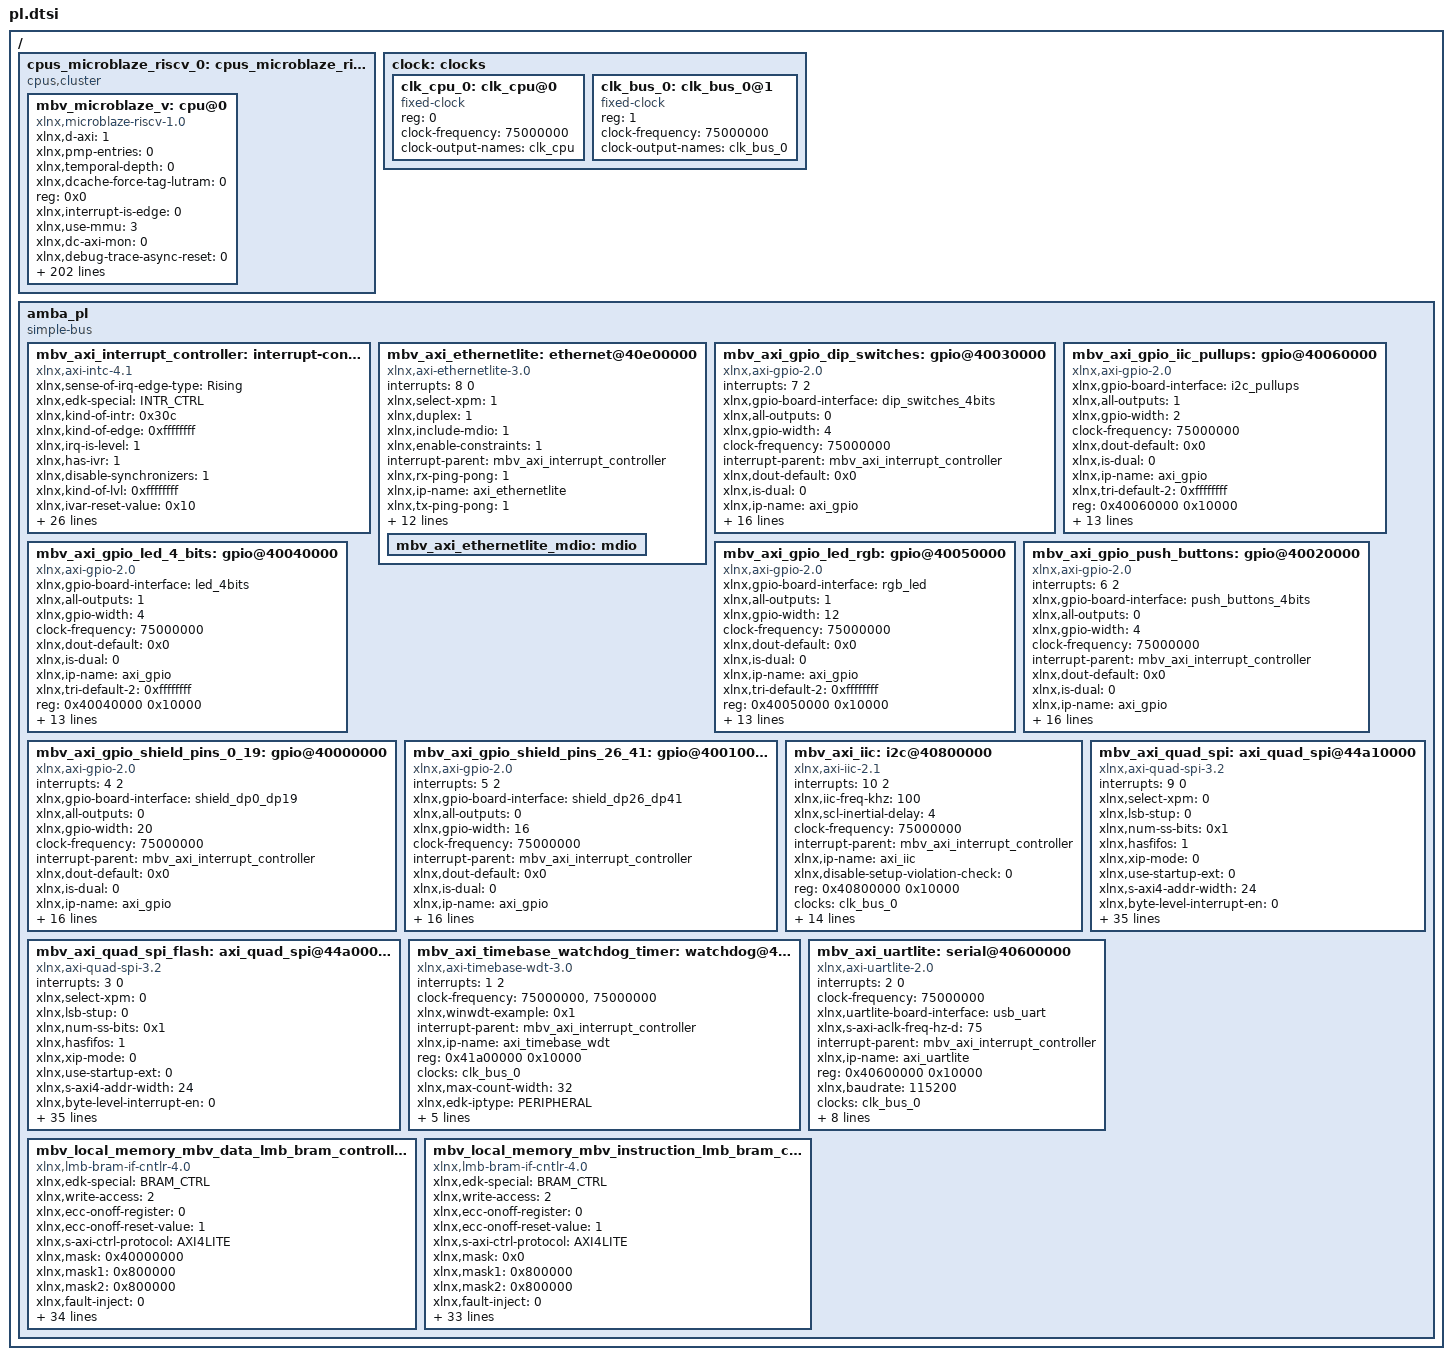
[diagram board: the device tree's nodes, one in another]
/ {
	cpus_microblaze_riscv_0: cpus_microblaze_riscv@0 {
		#cpu-mask-cells = <1>;
		compatible = "cpus,cluster";
		#address-cells = <1>;
		#size-cells = <0>;
		mbv_microblaze_v: cpu@0 {
			xlnx,d-axi = <1>;
			xlnx,pmp-entries = <0>;
			xlnx,temporal-depth = <0>;
			xlnx,dcache-force-tag-lutram = <0>;
			reg = <0x0>;
			xlnx,interrupt-is-edge = <0>;
			xlnx,use-mmu = <3>;
			xlnx,dc-axi-mon = <0>;
			xlnx,debug-trace-async-reset = <0>;
			xlnx,part = "xc7a35ticsg324-1l";
			xlnx,use-config-reset = <0>;
			xlnx,family = "artix7";
			xlnx,use-sleep = <0>;
			xlnx,d-lmb = <1>;
			xlnx,enable-discrete-ports = <0>;
			xlnx,debug-interface = <0>;
			xlnx,use-ext-brk = <0>;
			xlnx,debug-enabled = <1>;
			xlnx,daddr-size = <32>;
			xlnx,use-extended-fsl-instr = <0>;
			xlnx,branch-target-cache-size = <0>;
			bus-handle = <&amba_pl>;
			xlnx,pmp-addr0 = <0x0>;
			xlnx,pmp-addr1 = <0x0>;
			xlnx,pmp-addr2 = <0x0>;
			xlnx,pmp-addr3 = <0x0>;
			xlnx,pmp-addr4 = <0x0>;
			xlnx,edk-special = "microblaze_riscv";
			xlnx,use-dcache = <0>;
			xlnx,pmp-addr5 = <0x0>;
			xlnx,use-muldiv = <2>;
			xlnx,pmp-addr6 = <0x0>;
			xlnx,use-axi-dp-ext-addr = <0>;
			xlnx,pmp-addr7 = <0x0>;
			xlnx,pmp-addr8 = <0x0>;
			xlnx,pmp-addr9 = <0x0>;
			xlnx,i-axi = <0>;
			xlnx,icache-streams = <0>;
			xlnx,i-lmb-has-prot = <0>;
			xlnx,num-sync-ff-dbg-clk = <1>;
			xlnx,icache-byte-size = <8192>;
			xlnx,pmp-addr10 = <0x0>;
			d-cache-size = <8192>;
			xlnx,pmp-addr11 = <0x0>;
			xlnx,pmp-addr12 = <0x0>;
			xlnx,pmp-addr13 = <0x0>;
			xlnx,pmp-addr14 = <0x0>;
			xlnx,pmp-addr15 = <0x0>;
			xlnx,avoid-primitives = <0>;
			xlnx,pmp-addr16 = <0x0>;
			xlnx,pmp-addr17 = <0x0>;
			xlnx,pmp-addr18 = <0x0>;
			xlnx,pdaddr-size = <34>;
			xlnx,pmp-addr19 = <0x0>;
			xlnx,pmp-addr20 = <0x0>;
			xlnx,pmp-addr21 = <0x0>;
			xlnx,i-lmb = <1>;
			xlnx,pmp-addr22 = <0x0>;
			xlnx,lmb-data-size = <32>;
			xlnx,lockstep-select = <0>;
			xlnx,pmp-addr23 = <0x0>;
			timebase-frequency = <75000000>;
			xlnx,pmp-addr24 = <0x0>;
			xlnx,dcache-data-width = <0>;
			xlnx,icache-force-tag-lutram = <0>;
			xlnx,pmp-addr25 = <0x0>;
			xlnx,pmp-addr26 = <0x0>;
			xlnx,use-branch-target-cache = <0>;
			xlnx,pmp-addr27 = <0x0>;
			xlnx,number-of-pc-brk = <8>;
			xlnx,pmp-addr28 = <0x0>;
			xlnx,imprecise-exceptions = <0>;
			xlnx,pmp-addr29 = <0x0>;
			xlnx,pmp-addr30 = <0x0>;
			xlnx,pmp-addr31 = <0x0>;
			xlnx,pmp-addr32 = <0x0>;
			model = "microblaze_riscv,1.0";
			xlnx,pmp-addr33 = <0x0>;
			xlnx,pmp-addr34 = <0x0>;
			xlnx,pmp-addr35 = <0x0>;
			xlnx,pmp-addr36 = <0x0>;
			d-cache-highaddr = <0x3fffffff>;
			xlnx,optimization = <0>;
			xlnx,pmp-addr37 = <0x0>;
			xlnx,pmp-addr38 = <0x0>;
			xlnx,pmp-addr39 = <0x0>;
			xlnx,pmp-addr40 = <0x0>;
			xlnx,pmp-addr41 = <0x0>;
			xlnx,d-lmb-mon = <0>;
			xlnx,pmp-addr42 = <0x0>;
			xlnx,pmp-addr43 = <0x0>;
			xlnx,pmp-addr44 = <0x0>;
			xlnx,pmp-addr45 = <0x0>;
			xlnx,pmp-addr46 = <0x0>;
			xlnx,pmp-addr47 = <0x0>;
			xlnx,pmp-addr48 = <0x0>;
			xlnx,fault-tolerant = <0>;
			xlnx,pmp-addr49 = <0x0>;
			xlnx,pmp-addr50 = <0x0>;
			xlnx,pmp-addr51 = <0x0>;
			xlnx,pmp-enhancements = <0>;
			d-cache-line-size = <16>;
			xlnx,mmu-privileged-instr = <0>;
			xlnx,pmp-addr52 = <0x0>;
			clock-frequency = <75000000>;
			xlnx,pmp-addr53 = <0x0>;
			xlnx,pmp-addr54 = <0x0>;
			xlnx,pmp-addr55 = <0x0>;
			xlnx,i-lmb-protocol = <0>;
			xlnx,pmp-addr56 = <0x0>;
			xlnx,pmp-addr57 = <0x0>;
			xlnx,dp-axi-mon = <0>;
			xlnx,pmp-addr58 = <0x0>;
			xlnx,pmp-addr59 = <0x0>;
			xlnx,pmp-addr60 = <0x0>;
			xlnx,pmp-addr61 = <0x0>;
			xlnx,pmp-addr62 = <0x0>;
			xlnx,pmp-addr63 = <0x0>;
			xlnx,debug-external-trace = <1>;
			xlnx,addr-size = <32>;
			xlnx,debug-num-progbuf = <2>;
			xlnx,debug-event-counters = <13>;
			xlnx,edk-iptype = "PROCESSOR";
			xlnx,debug-latency-counters = <8>;
			xlnx,interconnect = <2>;
			xlnx,edge-is-positive = <1>;
			xlnx,use-icache = <0>;
			xlnx,async-wakeup = <3>;
			xlnx,s-axi = <0>;
			xlnx,use-ext-nm-brk = <0>;
			xlnx,ic-axi-mon = <0>;
			xlnx,archid = <0x1>;
			xlnx,num-sync-ff-clk-irq = <1>;
			xlnx,freq = <75000000>;
			xlnx,lockstep-master = <0>;
			xlnx,pmp-cfg0 = <0x0>;
			xlnx,pmp-cfg1 = <0x0>;
			xlnx,iaddr-size = <32>;
			xlnx,interrupt-mon = <0>;
			xlnx,pmp-cfg2 = <0x0>;
			xlnx,number-of-wr-addr-brk = <4>;
			xlnx,pmp-cfg3 = <0x0>;
			xlnx,pmp-cfg4 = <0x0>;
			xlnx,use-interrupt = <2>;
			xlnx,pmp-cfg5 = <0x0>;
			xlnx,async-interrupt = <1>;
			xlnx,pc-width = <17>;
			xlnx,pmp-cfg6 = <0x0>;
			xlnx,icache-victims = <0>;
			xlnx,pmp-cfg7 = <0x0>;
			xlnx,pmp-cfg8 = <0x0>;
			xlnx,pmp-cfg9 = <0x0>;
			xlnx,use-bitman-a = <1>;
			xlnx,use-bitman-b = <1>;
			xlnx,use-bitman-c = <1>;
			xlnx,i-lmb-mon = <0>;
			xlnx,dcache-byte-size = <8192>;
			xlnx,data-size = <32>;
			compatible = "xlnx,microblaze-riscv-1.0" , "xlnx,microblaze_riscv";
			xlnx,pmp-debug-inhibit = <0x0>;
			xlnx,use-sstc = <1>;
			xlnx,fsl-exception = <0>;
			xlnx,dcache-use-writeback = <0>;
			device_type = "cpu";
			xlnx,impid = <0x1>;
			xlnx,use-bitman-s = <1>;
			xlnx,base-vectors = <0x0>;
			xlnx,icache-line-len = <4>;
			xlnx,d-lmb-has-prot = <0>;
			xlnx,use-barrel = <1>;
			xlnx,misaligned-exceptions = <1>;
			xlnx,piaddr-size = <34>;
			xlnx,use-bitman = <15>;
			xlnx,dcache-line-len = <4>;
			xlnx,num-sync-ff-clk = <2>;
			xlnx,memory-ip-list = "mbv_local_memory_mbv_instruction_lmb_bram_controller_memory" , "mbv_local_memory_mbv_data_lmb_bram_controller_memory";
			xlnx,number-of-rd-addr-brk = <4>;
			xlnx,use-counters = <1>;
			xlnx,lockstep-slave = <0>;
			interrupt-handle = <&mbv_axi_interrupt_controller>;
			xlnx,pmp-cfg10 = <0x0>;
			xlnx,pmp-cfg11 = <0x0>;
			xlnx,debug-profile-size = <0>;
			xlnx,pmp-cfg12 = <0x0>;
			xlnx,pmp-cfg13 = <0x0>;
			xlnx,pmp-cfg14 = <0x0>;
			xlnx,pmp-cfg15 = <0x0>;
			xlnx,debug-counter-width = <64>;
			xlnx,icache-data-width = <0>;
			xlnx,ip-name = "microblaze_riscv";
			xlnx,ip-axi-mon = <0>;
			xlnx,d-lmb-protocol = <0>;
			xlnx,trace = <0>;
			xlnx,ill-instr-exception = <2>;
			xlnx,debug-trace-size = <0>;
			xlnx,pmp-granularity = <2>;
			xlnx,num-sync-ff-dbg-trace-clk = <2>;
			xlnx,ecc-use-ce-exception = <0>;
			xlnx,num-sync-ff-clk-debug = <2>;
			xlnx,use-atomic = <1>;
			xlnx,g-template-list = <0>;
			xlnx,trap-enhancement = <0>;
			xlnx,hartid = <0x0>;
			xlnx,use-fpu = <0>;
			xlnx,use-non-secure = <0>;
			d-cache-baseaddr = <0x0>;
			xlnx,use-compression = <1>;
			xlnx,instr-size = <32>;
			xlnx,fsl-links = <0>;
			xlnx,dcache-victims = <0>;
			xlnx,pmp-read-only = <0x0>;
		};
	};
	clock: clocks {
		#address-cells = <1>;
		#size-cells = <0>;
		clk_cpu_0: clk_cpu@0 {
			compatible = "fixed-clock";
			reg = <0>;
			clock-frequency = <75000000>;
			clock-output-names = "clk_cpu";
			#clock-cells = <0>;
		};
		clk_bus_0: clk_bus_0@1 {
			compatible = "fixed-clock";
			reg = <1>;
			clock-frequency = <75000000>;
			clock-output-names = "clk_bus_0";
			#clock-cells = <0>;
		};
	};
	amba_pl: amba_pl {
		ranges;
		compatible = "simple-bus";
		#address-cells = <1>;
		#size-cells = <1>;
		mbv_axi_interrupt_controller: interrupt-controller@41200000 {
			#interrupt-cells = <2>;
			xlnx,sense-of-irq-edge-type = "Rising";
			xlnx,edk-special = "INTR_CTRL";
			xlnx,kind-of-intr = <0x30c>;
			xlnx,kind-of-edge = <0xffffffff>;
			xlnx,irq-is-level = <1>;
			xlnx,has-ivr = <1>;
			compatible = "xlnx,axi-intc-4.1" , "xlnx,xps-intc-1.00.a";
			xlnx,disable-synchronizers = <1>;
			xlnx,kind-of-lvl = <0xffffffff>;
			xlnx,ivar-reset-value = <0x10>;
			xlnx,irq-active = <0x1>;
			xlnx,en-cascade-mode = <0>;
			xlnx,ip-name = "axi_intc";
			xlnx,has-ilr = <0>;
			reg = <0x41200000 0x10000>;
			xlnx,addr-width = <0x20>;
			xlnx,s-axi-aclk-freq-mhz = <75>;
			xlnx,num-sw-intr = <0>;
			xlnx,irq-connection = <0>;
			xlnx,num-intr-inputs = <0xb>;
			xlnx,has-sie = <1>;
			xlnx,enable-async = <0>;
			xlnx,has-cie = <1>;
			xlnx,num-sync-ff = <2>;
			xlnx,edk-iptype = "PERIPHERAL";
			xlnx,mb-clk-not-connected = <1>;
			xlnx,has-ipr = <1>;
			xlnx,sense-of-irq-level-type = "Active_High";
			xlnx,cascade-master = <0>;
			xlnx,processor-clk-freq-mhz = <75>;
			status = "okay";
			xlnx,is-fast = <0x1>;
			xlnx,has-fast = <1>;
			xlnx,ivar-rst-val = <0x10>;
			interrupt-controller;
			xlnx,async-intr = <0xfffff900>;
			xlnx,name = "mbv_axi_interrupt_controller";
		};
		mbv_axi_ethernetlite: ethernet@40e00000 {
			interrupts = < 8 0 >;
			xlnx,select-xpm = <1>;
			compatible = "xlnx,axi-ethernetlite-3.0" , "xlnx,axi-ethernetlite-3.0" , "xlnx,xps-ethernetlite-1.00.a";
			xlnx,duplex = <1>;
			xlnx,include-mdio = <1>;
			xlnx,enable-constraints = <1>;
			interrupt-parent = <&mbv_axi_interrupt_controller>;
			xlnx,rx-ping-pong = <1>;
			xlnx,ip-name = "axi_ethernetlite";
			xlnx,tx-ping-pong = <1>;
			reg = <0x40e00000 0x10000>;
			xlnx,mii-board-interface = "eth_mii";
			xlnx,mdio-board-interface = "eth_mdio_mdc";
			xlnx,edk-iptype = "PERIPHERAL";
			xlnx,include-global-buffers = <1>;
			local-mac-address = [ 00 0a 23 00 00 00 ];
			status = "okay";
			xlnx,include-internal-loopback = <0>;
			xlnx,use-board-flow;
			xlnx,use-internal = <0>;
			interrupt-names = "ip2intc_irpt";
			xlnx,name = "mbv_axi_ethernetlite";
			xlnx,axi-aclk-freq-mhz = <75>;
			xlnx,s-axi-id-width = <1>;
			mbv_axi_ethernetlite_mdio: mdio {
				#address-cells = <1>;
				#size-cells = <0>;
			};
		};
		mbv_axi_gpio_dip_switches: gpio@40030000 {
			#interrupt-cells = <2>;
			interrupts = < 7 2 >;
			xlnx,gpio-board-interface = "dip_switches_4bits";
			compatible = "xlnx,axi-gpio-2.0" , "xlnx,xps-gpio-1.00.a";
			xlnx,all-outputs = <0>;
			#gpio-cells = <2>;
			xlnx,gpio-width = <4>;
			clock-frequency = <75000000>;
			interrupt-parent = <&mbv_axi_interrupt_controller>;
			xlnx,dout-default = <0x0>;
			xlnx,is-dual = <0>;
			xlnx,ip-name = "axi_gpio";
			xlnx,tri-default-2 = <0xffffffff>;
			reg = <0x40030000 0x10000>;
			xlnx,all-inputs-2 = <0>;
			clocks = <&clk_bus_0>;
			xlnx,all-outputs-2 = <0>;
			gpio-controller;
			xlnx,interrupt-present = <1>;
			xlnx,gpio2-board-interface = "Custom";
			xlnx,edk-iptype = "PERIPHERAL";
			xlnx,dout-default-2 = <0x0>;
			status = "okay";
			xlnx,gpio2-width = <32>;
			clock-names = "s_axi_aclk";
			xlnx,use-board-flow;
			interrupt-controller;
			interrupt-names = "ip2intc_irpt";
			xlnx,tri-default = <0xffffffff>;
			xlnx,name = "mbv_axi_gpio_dip_switches";
			xlnx,all-inputs = <1>;
		};
		mbv_axi_gpio_iic_pullups: gpio@40060000 {
			xlnx,gpio-board-interface = "i2c_pullups";
			compatible = "xlnx,axi-gpio-2.0" , "xlnx,xps-gpio-1.00.a";
			xlnx,all-outputs = <1>;
			#gpio-cells = <2>;
			xlnx,gpio-width = <2>;
			clock-frequency = <75000000>;
			xlnx,dout-default = <0x0>;
			xlnx,is-dual = <0>;
			xlnx,ip-name = "axi_gpio";
			xlnx,tri-default-2 = <0xffffffff>;
			reg = <0x40060000 0x10000>;
			xlnx,all-inputs-2 = <0>;
			clocks = <&clk_bus_0>;
			xlnx,all-outputs-2 = <0>;
			gpio-controller;
			xlnx,interrupt-present = <0>;
			xlnx,gpio2-board-interface = "Custom";
			xlnx,edk-iptype = "PERIPHERAL";
			xlnx,dout-default-2 = <0x0>;
			status = "okay";
			xlnx,gpio2-width = <32>;
			clock-names = "s_axi_aclk";
			xlnx,use-board-flow;
			xlnx,tri-default = <0xffffffff>;
			xlnx,name = "mbv_axi_gpio_iic_pullups";
			xlnx,all-inputs = <0>;
		};
		mbv_axi_gpio_led_4_bits: gpio@40040000 {
			xlnx,gpio-board-interface = "led_4bits";
			compatible = "xlnx,axi-gpio-2.0" , "xlnx,xps-gpio-1.00.a";
			xlnx,all-outputs = <1>;
			#gpio-cells = <2>;
			xlnx,gpio-width = <4>;
			clock-frequency = <75000000>;
			xlnx,dout-default = <0x0>;
			xlnx,is-dual = <0>;
			xlnx,ip-name = "axi_gpio";
			xlnx,tri-default-2 = <0xffffffff>;
			reg = <0x40040000 0x10000>;
			xlnx,all-inputs-2 = <0>;
			clocks = <&clk_bus_0>;
			xlnx,all-outputs-2 = <0>;
			gpio-controller;
			xlnx,interrupt-present = <0>;
			xlnx,gpio2-board-interface = "Custom";
			xlnx,edk-iptype = "PERIPHERAL";
			xlnx,dout-default-2 = <0x0>;
			status = "okay";
			xlnx,gpio2-width = <32>;
			clock-names = "s_axi_aclk";
			xlnx,use-board-flow;
			xlnx,tri-default = <0xffffffff>;
			xlnx,name = "mbv_axi_gpio_led_4_bits";
			xlnx,all-inputs = <0>;
		};
		mbv_axi_gpio_led_rgb: gpio@40050000 {
			xlnx,gpio-board-interface = "rgb_led";
			compatible = "xlnx,axi-gpio-2.0" , "xlnx,xps-gpio-1.00.a";
			xlnx,all-outputs = <1>;
			#gpio-cells = <2>;
			xlnx,gpio-width = <12>;
			clock-frequency = <75000000>;
			xlnx,dout-default = <0x0>;
			xlnx,is-dual = <0>;
			xlnx,ip-name = "axi_gpio";
			xlnx,tri-default-2 = <0xffffffff>;
			reg = <0x40050000 0x10000>;
			xlnx,all-inputs-2 = <0>;
			clocks = <&clk_bus_0>;
			xlnx,all-outputs-2 = <0>;
			gpio-controller;
			xlnx,interrupt-present = <0>;
			xlnx,gpio2-board-interface = "Custom";
			xlnx,edk-iptype = "PERIPHERAL";
			xlnx,dout-default-2 = <0x0>;
			status = "okay";
			xlnx,gpio2-width = <32>;
			clock-names = "s_axi_aclk";
			xlnx,use-board-flow;
			xlnx,tri-default = <0xffffffff>;
			xlnx,name = "mbv_axi_gpio_led_rgb";
			xlnx,all-inputs = <0>;
		};
		mbv_axi_gpio_push_buttons: gpio@40020000 {
			#interrupt-cells = <2>;
			interrupts = < 6 2 >;
			xlnx,gpio-board-interface = "push_buttons_4bits";
			compatible = "xlnx,axi-gpio-2.0" , "xlnx,xps-gpio-1.00.a";
			xlnx,all-outputs = <0>;
			#gpio-cells = <2>;
			xlnx,gpio-width = <4>;
			clock-frequency = <75000000>;
			interrupt-parent = <&mbv_axi_interrupt_controller>;
			xlnx,dout-default = <0x0>;
			xlnx,is-dual = <0>;
			xlnx,ip-name = "axi_gpio";
			xlnx,tri-default-2 = <0xffffffff>;
			reg = <0x40020000 0x10000>;
			xlnx,all-inputs-2 = <0>;
			clocks = <&clk_bus_0>;
			xlnx,all-outputs-2 = <0>;
			gpio-controller;
			xlnx,interrupt-present = <1>;
			xlnx,gpio2-board-interface = "Custom";
			xlnx,edk-iptype = "PERIPHERAL";
			xlnx,dout-default-2 = <0x0>;
			status = "okay";
			xlnx,gpio2-width = <32>;
			clock-names = "s_axi_aclk";
			xlnx,use-board-flow;
			interrupt-controller;
			interrupt-names = "ip2intc_irpt";
			xlnx,tri-default = <0xffffffff>;
			xlnx,name = "mbv_axi_gpio_push_buttons";
			xlnx,all-inputs = <1>;
		};
		mbv_axi_gpio_shield_pins_0_19: gpio@40000000 {
			#interrupt-cells = <2>;
			interrupts = < 4 2 >;
			xlnx,gpio-board-interface = "shield_dp0_dp19";
			compatible = "xlnx,axi-gpio-2.0" , "xlnx,xps-gpio-1.00.a";
			xlnx,all-outputs = <0>;
			#gpio-cells = <2>;
			xlnx,gpio-width = <20>;
			clock-frequency = <75000000>;
			interrupt-parent = <&mbv_axi_interrupt_controller>;
			xlnx,dout-default = <0x0>;
			xlnx,is-dual = <0>;
			xlnx,ip-name = "axi_gpio";
			xlnx,tri-default-2 = <0xffffffff>;
			reg = <0x40000000 0x10000>;
			xlnx,all-inputs-2 = <0>;
			clocks = <&clk_bus_0>;
			xlnx,all-outputs-2 = <0>;
			gpio-controller;
			xlnx,interrupt-present = <1>;
			xlnx,gpio2-board-interface = "Custom";
			xlnx,edk-iptype = "PERIPHERAL";
			xlnx,dout-default-2 = <0x0>;
			status = "okay";
			xlnx,gpio2-width = <32>;
			clock-names = "s_axi_aclk";
			xlnx,use-board-flow;
			interrupt-controller;
			interrupt-names = "ip2intc_irpt";
			xlnx,tri-default = <0xffffffff>;
			xlnx,name = "mbv_axi_gpio_shield_pins_0_19";
			xlnx,all-inputs = <0>;
		};
		mbv_axi_gpio_shield_pins_26_41: gpio@40010000 {
			#interrupt-cells = <2>;
			interrupts = < 5 2 >;
			xlnx,gpio-board-interface = "shield_dp26_dp41";
			compatible = "xlnx,axi-gpio-2.0" , "xlnx,xps-gpio-1.00.a";
			xlnx,all-outputs = <0>;
			#gpio-cells = <2>;
			xlnx,gpio-width = <16>;
			clock-frequency = <75000000>;
			interrupt-parent = <&mbv_axi_interrupt_controller>;
			xlnx,dout-default = <0x0>;
			xlnx,is-dual = <0>;
			xlnx,ip-name = "axi_gpio";
			xlnx,tri-default-2 = <0xffffffff>;
			reg = <0x40010000 0x10000>;
			xlnx,all-inputs-2 = <0>;
			clocks = <&clk_bus_0>;
			xlnx,all-outputs-2 = <0>;
			gpio-controller;
			xlnx,interrupt-present = <1>;
			xlnx,gpio2-board-interface = "Custom";
			xlnx,edk-iptype = "PERIPHERAL";
			xlnx,dout-default-2 = <0x0>;
			status = "okay";
			xlnx,gpio2-width = <32>;
			clock-names = "s_axi_aclk";
			xlnx,use-board-flow;
			interrupt-controller;
			interrupt-names = "ip2intc_irpt";
			xlnx,tri-default = <0xffffffff>;
			xlnx,name = "mbv_axi_gpio_shield_pins_26_41";
			xlnx,all-inputs = <0>;
		};
		mbv_axi_iic: i2c@40800000 {
			interrupts = < 10 2 >;
			xlnx,iic-freq-khz = <100>;
			compatible = "xlnx,axi-iic-2.1" , "xlnx,xps-iic-2.00.a";
			xlnx,scl-inertial-delay = <4>;
			clock-frequency = <75000000>;
			interrupt-parent = <&mbv_axi_interrupt_controller>;
			xlnx,ip-name = "axi_iic";
			xlnx,disable-setup-violation-check = <0>;
			reg = <0x40800000 0x10000>;
			clocks = <&clk_bus_0>;
			xlnx,gpo-width = <1>;
			xlnx,edk-iptype = "PERIPHERAL";
			xlnx,static-timing-reg-width = <0>;
			xlnx,sda-level = <1>;
			status = "okay";
			xlnx,use-board-flow;
			xlnx,ten-bit-adr = <0>;
			xlnx,default-value = <0x0>;
			interrupt-names = "iic2intc_irpt";
			xlnx,iic-board-interface = "i2c";
			xlnx,timing-reg-width = <32>;
			xlnx,iic-freq = <100000>;
			xlnx,smbus-pmbus-host = <0>;
			xlnx,name = "mbv_axi_iic";
			xlnx,axi-aclk-freq-mhz = <75>;
			xlnx,sda-inertial-delay = <4>;
		};
		mbv_axi_quad_spi: axi_quad_spi@44a10000 {
			interrupts = < 9 0 >;
			xlnx,select-xpm = <0>;
			compatible = "xlnx,axi-quad-spi-3.2" , "xlnx,xps-spi-2.00.a";
			xlnx,lsb-stup = <0>;
			xlnx,num-ss-bits = <0x1>;
			xlnx,hasfifos = <1>;
			xlnx,xip-mode = <0>;
			xlnx,use-startup-ext = <0>;
			xlnx,s-axi4-addr-width = <24>;
			xlnx,byte-level-interrupt-en = <0>;
			num-cs = <0x1>;
			xlnx,xip-perf-mode = <1>;
			xlnx,sck-ratio = <16>;
			xlnx,s-axi4-id-width = <1>;
			fifo-size = <256>;
			interrupt-parent = <&mbv_axi_interrupt_controller>;
			xlnx,multiples16 = <1>;
			xlnx,master-mode = <1>;
			xlnx,shared-startup = <0>;
			xlnx,ip-name = "axi_quad_spi";
			xlnx,qspi-board-interface = "spi";
			reg = <0x44a10000 0x10000>;
			xlnx,dual-quad-mode = <0>;
			xlnx,new-seq-en = <1>;
			bits-per-word = <32>;
			xlnx,num-transfer-bits = <32>;
			xlnx,spi-memory = <3>;
			xlnx,s-axi4-data-width = <32>;
			xlnx,edk-iptype = "PERIPHERAL";
			xlnx,slaveonly = <0>;
			xlnx,use-startup-int = <0>;
			xlnx,use-startup = <0>;
			xlnx,type-of-axi4-interface = <1>;
			xlnx,async-clk = <0>;
			xlnx,spi-mode = <0>;
			xlnx,sck-ratio1 = <1>;
			status = "okay";
			xlnx,fifo-depth = <256>;
			xlnx,use-board-flow;
			xlnx,uc-family = <0>;
			xlnx,spi-mem-addr-bits = <24>;
			xlnx,axi-interface = <1>;
			interrupt-names = "ip2intc_irpt";
			xlnx,Axi4-address = <0x44a10000>;
			xlnx,fifo-included = <1>;
			xlnx,sub-family = "artix7";
			xlnx,name = "mbv_axi_quad_spi";
		};
		mbv_axi_quad_spi_flash: axi_quad_spi@44a00000 {
			interrupts = < 3 0 >;
			xlnx,select-xpm = <0>;
			compatible = "xlnx,axi-quad-spi-3.2" , "xlnx,xps-spi-2.00.a";
			xlnx,lsb-stup = <0>;
			xlnx,num-ss-bits = <0x1>;
			xlnx,hasfifos = <1>;
			xlnx,xip-mode = <0>;
			xlnx,use-startup-ext = <0>;
			xlnx,s-axi4-addr-width = <24>;
			xlnx,byte-level-interrupt-en = <0>;
			num-cs = <0x1>;
			xlnx,xip-perf-mode = <1>;
			xlnx,sck-ratio = <2>;
			xlnx,s-axi4-id-width = <1>;
			fifo-size = <256>;
			interrupt-parent = <&mbv_axi_interrupt_controller>;
			xlnx,multiples16 = <1>;
			xlnx,master-mode = <1>;
			xlnx,shared-startup = <0>;
			xlnx,ip-name = "axi_quad_spi";
			xlnx,qspi-board-interface = "qspi_flash";
			reg = <0x44a00000 0x10000>;
			xlnx,dual-quad-mode = <0>;
			xlnx,new-seq-en = <1>;
			bits-per-word = <8>;
			xlnx,num-transfer-bits = <8>;
			xlnx,spi-memory = <3>;
			xlnx,s-axi4-data-width = <32>;
			xlnx,edk-iptype = "PERIPHERAL";
			xlnx,slaveonly = <0>;
			xlnx,use-startup-int = <0>;
			xlnx,use-startup = <0>;
			xlnx,type-of-axi4-interface = <1>;
			xlnx,async-clk = <0>;
			xlnx,spi-mode = <2>;
			xlnx,sck-ratio1 = <1>;
			status = "okay";
			xlnx,fifo-depth = <256>;
			xlnx,use-board-flow;
			xlnx,uc-family = <0>;
			xlnx,spi-mem-addr-bits = <24>;
			xlnx,axi-interface = <1>;
			interrupt-names = "ip2intc_irpt";
			xlnx,Axi4-address = <0x44a00000>;
			xlnx,fifo-included = <1>;
			xlnx,sub-family = "artix7";
			xlnx,name = "mbv_axi_quad_spi_flash";
		};
		mbv_axi_timebase_watchdog_timer: watchdog@41a00000 {
			compatible = "xlnx,axi-timebase-wdt-3.0" , "xlnx,xps-timebase-wdt-1.00.a";
			interrupts = < 1 2 >;
			clock-frequency = <75000000> , <75000000>;
			xlnx,winwdt-example = <0x1>;
			interrupt-parent = <&mbv_axi_interrupt_controller>;
			xlnx,ip-name = "axi_timebase_wdt";
			reg = <0x41a00000 0x10000>;
			clocks = <&clk_bus_0>;
			xlnx,max-count-width = <32>;
			xlnx,edk-iptype = "PERIPHERAL";
			xlnx,sst-count-width = <8>;
			xlnx,wdt-enable-once = <0x1>;
			status = "okay";
			interrupt-names = "wdt_interrupt";
			xlnx,enable-window-wdt = <0x1>;
			xlnx,name = "mbv_axi_timebase_watchdog_timer";
			xlnx,wdt-interval = <0x1e>;
		};
		mbv_axi_uartlite: serial@40600000 {
			interrupts = < 2 0 >;
			compatible = "xlnx,axi-uartlite-2.0" , "xlnx,xps-uartlite-1.00.a";
			clock-frequency = <75000000>;
			xlnx,uartlite-board-interface = "usb_uart";
			xlnx,s-axi-aclk-freq-hz-d = <75>;
			interrupt-parent = <&mbv_axi_interrupt_controller>;
			xlnx,ip-name = "axi_uartlite";
			reg = <0x40600000 0x10000>;
			xlnx,baudrate = <115200>;
			clocks = <&clk_bus_0>;
			current-speed = <115200>;
			xlnx,use-parity = <0>;
			xlnx,edk-iptype = "PERIPHERAL";
			xlnx,odd-parity = <0>;
			status = "okay";
			xlnx,use-board-flow;
			interrupt-names = "interrupt";
			xlnx,name = "mbv_axi_uartlite";
			xlnx,data-bits = <8>;
			xlnx,parity = "No_Parity";
		};
		mbv_local_memory_mbv_data_lmb_bram_controller: lmb_bram_if_cntlr@0 {
			xlnx,edk-special = "BRAM_CTRL";
			xlnx,write-access = <2>;
			compatible = "xlnx,lmb-bram-if-cntlr-4.0" , "xlnx,axi-bram-ctrl";
			xlnx,ecc-onoff-register = <0>;
			xlnx,ecc-onoff-reset-value = <1>;
			xlnx,s-axi-ctrl-protocol = "AXI4LITE";
			xlnx,mask = <0x40000000>;
			xlnx,mask1 = <0x800000>;
			xlnx,mask2 = <0x800000>;
			xlnx,fault-inject = <0>;
			xlnx,mask3 = <0x800000>;
			xlnx,ip-name = "lmb_bram_if_cntlr";
			xlnx,arbitration = <0>;
			xlnx,num-lmb = <1>;
			xlnx,mask4 = <0x800000>;
			reg = <0x00000000 0x20000>;
			xlnx,s-axi-ctrl-addr-width = <32>;
			xlnx,mask5 = <0x800000>;
			xlnx,ecc-status-registers = <0>;
			xlnx,prot-cfg = <0xff>;
			xlnx,mask6 = <0x800000>;
			xlnx,lmb-protocol = <0>;
			xlnx,ce-counter-width = <0>;
			xlnx,prot-cfg1 = <0xff>;
			xlnx,mask7 = <0x800000>;
			xlnx,ecc = <0>;
			xlnx,edk-iptype = "PERIPHERAL";
			xlnx,prot-cfg2 = <0xff>;
			xlnx,lmb-dwidth = <32>;
			xlnx,interconnect = <0>;
			xlnx,ce-failing-registers = <0>;
			xlnx,prot-cfg3 = <0xff>;
			xlnx,ue-failing-registers = <0>;
			xlnx,prot-cfg4 = <0xff>;
			xlnx,lmb-has-prot = <0>;
			status = "okay";
			xlnx,data-width = <32>;
			xlnx,prot-cfg5 = <0xff>;
			xlnx,s-axi-ctrl-data-width = <32>;
			xlnx,prot-cfg6 = <0xff>;
			xlnx,bram-awidth = <32>;
			xlnx,prot-cfg7 = <0xff>;
			xlnx,lmb-awidth = <34>;
			xlnx,name = "mbv_local_memory_mbv_data_lmb_bram_controller";
		};
		mbv_local_memory_mbv_instruction_lmb_bram_controller: mbv_local_memory_mbv_instruction_lmb_bram_controller@0 {
			xlnx,edk-special = "BRAM_CTRL";
			xlnx,write-access = <2>;
			compatible = "xlnx,lmb-bram-if-cntlr-4.0" , "xlnx,axi-bram-ctrl";
			xlnx,ecc-onoff-register = <0>;
			xlnx,ecc-onoff-reset-value = <1>;
			xlnx,s-axi-ctrl-protocol = "AXI4LITE";
			xlnx,mask = <0x0>;
			xlnx,mask1 = <0x800000>;
			xlnx,mask2 = <0x800000>;
			xlnx,fault-inject = <0>;
			xlnx,mask3 = <0x800000>;
			xlnx,ip-name = "lmb_bram_if_cntlr";
			xlnx,arbitration = <0>;
			xlnx,num-lmb = <1>;
			xlnx,mask4 = <0x800000>;
			reg = <0x00000000 0x20000>;
			xlnx,s-axi-ctrl-addr-width = <32>;
			xlnx,mask5 = <0x800000>;
			xlnx,ecc-status-registers = <0>;
			xlnx,prot-cfg = <0xff>;
			xlnx,mask6 = <0x800000>;
			xlnx,lmb-protocol = <0>;
			xlnx,ce-counter-width = <0>;
			xlnx,prot-cfg1 = <0xff>;
			xlnx,mask7 = <0x800000>;
			xlnx,ecc = <0>;
			xlnx,edk-iptype = "PERIPHERAL";
			xlnx,prot-cfg2 = <0xff>;
			xlnx,lmb-dwidth = <32>;
			xlnx,interconnect = <0>;
			xlnx,ce-failing-registers = <0>;
			xlnx,prot-cfg3 = <0xff>;
			xlnx,ue-failing-registers = <0>;
			xlnx,prot-cfg4 = <0xff>;
			xlnx,lmb-has-prot = <0>;
			status = "okay";
			xlnx,prot-cfg5 = <0xff>;
			xlnx,s-axi-ctrl-data-width = <32>;
			xlnx,prot-cfg6 = <0xff>;
			xlnx,bram-awidth = <32>;
			xlnx,prot-cfg7 = <0xff>;
			xlnx,lmb-awidth = <34>;
			xlnx,name = "mbv_local_memory_mbv_instruction_lmb_bram_controller";
		};
	};
};
